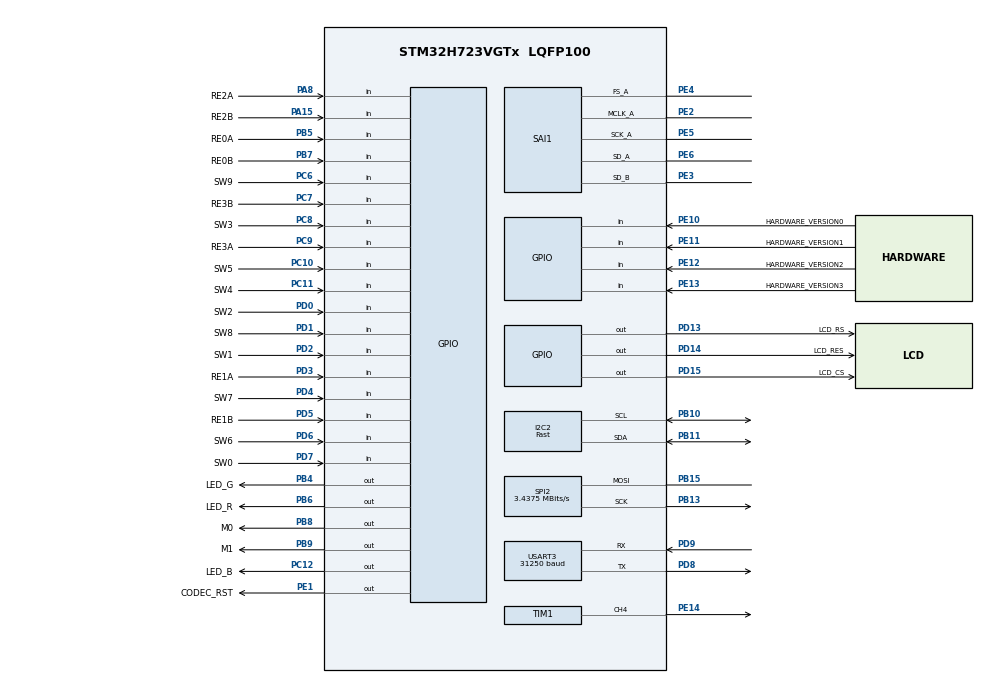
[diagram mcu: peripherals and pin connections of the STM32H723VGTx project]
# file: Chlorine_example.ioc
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CORTEX_M7.AccessPermission_Spec=MPU_REGION_FULL_ACCESS
CORTEX_M7.BaseAddress_Spec=0x30000000
CORTEX_M7.CPU_DCache=Enabled
CORTEX_M7.CPU_ICache=Enabled
CORTEX_M7.DisableExec_Spec=MPU_INSTRUCTION_ACCESS_ENABLE
CORTEX_M7.IsBufferable_Spec=MPU_ACCESS_BUFFERABLE
CORTEX_M7.Size_Spec=MPU_REGION_SIZE_512B
CORTEX_M7.SubRegionDisable_Spec=0x0
CORTEX_M7.default_mode_Activation=1
Dma.Request0=SAI1_A
Dma.Request1=SAI1_B
Dma.SAI1_A.0.Direction=DMA_PERIPH_TO_MEMORY
Dma.SAI1_A.0.EventEnable=DISABLE
Dma.SAI1_A.0.FIFOMode=DMA_FIFOMODE_DISABLE
Dma.SAI1_A.0.Instance=DMA1_Stream0
Dma.SAI1_A.0.MemDataAlignment=DMA_MDATAALIGN_WORD
Dma.SAI1_A.0.MemInc=DMA_MINC_ENABLE
Dma.SAI1_A.0.Mode=DMA_CIRCULAR
Dma.SAI1_A.0.PeriphDataAlignment=DMA_PDATAALIGN_WORD
Dma.SAI1_A.0.PeriphInc=DMA_PINC_DISABLE
Dma.SAI1_A.0.Polarity=HAL_DMAMUX_REQ_GEN_RISING
Dma.SAI1_A.0.Priority=DMA_PRIORITY_VERY_HIGH
Dma.SAI1_A.0.RequestNumber=1
Dma.SAI1_A.0.SignalID=NONE
Dma.SAI1_A.0.SyncEnable=DISABLE
Dma.SAI1_A.0.SyncPolarity=HAL_DMAMUX_SYNC_NO_EVENT
Dma.SAI1_A.0.SyncRequestNumber=1
Dma.SAI1_A.0.SyncSignalID=NONE
Dma.SAI1_B.1.Direction=DMA_MEMORY_TO_PERIPH
Dma.SAI1_B.1.EventEnable=DISABLE
Dma.SAI1_B.1.FIFOMode=DMA_FIFOMODE_DISABLE
Dma.SAI1_B.1.Instance=DMA1_Stream1
Dma.SAI1_B.1.MemDataAlignment=DMA_MDATAALIGN_WORD
Dma.SAI1_B.1.MemInc=DMA_MINC_ENABLE
Dma.SAI1_B.1.Mode=DMA_CIRCULAR
Dma.SAI1_B.1.PeriphDataAlignment=DMA_PDATAALIGN_WORD
Dma.SAI1_B.1.PeriphInc=DMA_PINC_DISABLE
Dma.SAI1_B.1.Polarity=HAL_DMAMUX_REQ_GEN_RISING
Dma.SAI1_B.1.Priority=DMA_PRIORITY_VERY_HIGH
Dma.SAI1_B.1.RequestNumber=1
Dma.SAI1_B.1.SignalID=NONE
Dma.SAI1_B.1.SyncEnable=DISABLE
Dma.SAI1_B.1.SyncPolarity=HAL_DMAMUX_SYNC_NO_EVENT
Dma.SAI1_B.1.SyncRequestNumber=1
Dma.SAI1_B.1.SyncSignalID=NONE
I2C2.I2C_Speed_Mode=I2C_Fast
I2C2.Timing=0x00D049FB
Mcu.Family=STM32H7
Mcu.Name=STM32H723VGTx
Mcu.Package=LQFP100
NVIC.DMA1_Stream0_IRQn=true\:0\:0\:false\:false\:true\:false\:true\:true
NVIC.DMA1_Stream1_IRQn=true\:0\:0\:false\:false\:true\:false\:true\:true
NVIC.PriorityGroup=NVIC_PRIORITYGROUP_4
NVIC.USART3_IRQn=true\:5\:0\:true\:false\:true\:true\:true\:true
PA13(JTMS/SWDIO).Mode=Serial_Wire
PA13(JTMS/SWDIO).Signal=DEBUG_JTMS-SWDIO
PA14(JTCK/SWCLK).Mode=Serial_Wire
PA14(JTCK/SWCLK).Signal=DEBUG_JTCK-SWCLK
PA15(JTDI).GPIO_Label=RE2B
PA15(JTDI).Signal=GPIO_Input
PA8.GPIO_Label=RE2A
PA8.Signal=GPIO_Input
PB10.Mode=I2C
PB10.Signal=I2C2_SCL
PB11.Mode=I2C
PB11.Signal=I2C2_SDA
PB13.Mode=Simplex_Bidirectional_Master
PB13.Signal=SPI2_SCK
PB15.Mode=Simplex_Bidirectional_Master
PB15.Signal=SPI2_MOSI
PB4(NJTRST).GPIO_Label=LED_G
PB4(NJTRST).Signal=GPIO_Output
PB5.GPIO_Label=RE0A
PB5.Signal=GPIO_Input
PB6.GPIO_Label=LED_R
PB6.Signal=GPIO_Output
PB7.GPIO_Label=RE0B
PB7.Signal=GPIO_Input
PB8.GPIO_Label=M0
PB8.Signal=GPIO_Output
PB9.GPIO_Label=M1
PB9.Signal=GPIO_Output
PC10.GPIO_Label=SW5
PC10.Signal=GPIO_Input
PC11.GPIO_Label=SW4
PC11.Signal=GPIO_Input
PC12.GPIO_Label=LED_B
PC12.Signal=GPIO_Output
PC6.GPIO_Label=SW9
PC6.Signal=GPIO_Input
PC7.GPIO_Label=RE3B
PC7.Signal=GPIO_Input
PC8.GPIO_Label=SW3
PC8.Signal=GPIO_Input
PC9.GPIO_Label=RE3A
PC9.Signal=GPIO_Input
PD0.GPIO_Label=SW2
PD0.Signal=GPIO_Input
PD1.GPIO_Label=SW8
PD1.Signal=GPIO_Input
PD13.GPIO_Label=LCD_RS
PD13.Signal=GPIO_Output
PD14.GPIO_Label=LCD_RES
PD14.Signal=GPIO_Output
PD15.GPIO_Label=LCD_CS
PD15.Signal=GPIO_Output
PD2.GPIO_Label=SW1
PD2.Signal=GPIO_Input
PD3.GPIO_Label=RE1A
PD3.Signal=GPIO_Input
PD4.GPIO_Label=SW7
PD4.Signal=GPIO_Input
PD5.GPIO_Label=RE1B
PD5.Signal=GPIO_Input
PD6.GPIO_Label=SW6
PD6.Signal=GPIO_Input
PD7.GPIO_Label=SW0
PD7.Signal=GPIO_Input
PD8.Mode=Asynchronous
PD8.Signal=USART3_TX
PD9.Mode=Asynchronous
PD9.Signal=USART3_RX
PE1.GPIO_Label=CODEC_RST
PE1.Signal=GPIO_Output
PE10.GPIO_Label=HARDWARE_VERSION0
PE10.Signal=GPIO_Input
PE11.GPIO_Label=HARDWARE_VERSION1
PE11.Signal=GPIO_Input
PE12.GPIO_Label=HARDWARE_VERSION2
PE12.Signal=GPIO_Input
PE13.GPIO_Label=HARDWARE_VERSION3
PE13.Signal=GPIO_Input
PE14.Signal=S_TIM1_CH4
PE2.Mode=SAI_A_MasterWithClock
PE2.Signal=SAI1_MCLK_A
PE3.Mode=SAI_B_SyncSlave
PE3.Signal=SAI1_SD_B
PE4.Mode=SAI_A_MasterWithClock
PE4.Signal=SAI1_FS_A
PE5.Mode=SAI_A_MasterWithClock
PE5.Signal=SAI1_SCK_A
PE6.Mode=SAI_A_MasterWithClock
PE6.Signal=SAI1_SD_A
PH0-OSC_IN.Mode=HSE-External-Oscillator
PH0-OSC_IN.Signal=RCC_OSC_IN
PH1-OSC_OUT.Mode=HSE-External-Oscillator
PH1-OSC_OUT.Signal=RCC_OSC_OUT
ProjectManager.HeapSize=0x200
ProjectManager.StackSize=0x400
ProjectManager.TargetToolchain=STM32CubeIDE
RCC.ADCFreq_Value=98333333.33333333
RCC.APB1Freq_Value=137500000
RCC.APB2Freq_Value=137500000
RCC.APB3Freq_Value=137500000
RCC.APB4Freq_Value=137500000
RCC.CortexFreq_Value=550000000
RCC.D1PPRE=RCC_APB3_DIV2
RCC.D2PPRE1=RCC_APB1_DIV2
RCC.D2PPRE2=RCC_APB2_DIV2
RCC.D3PPRE=RCC_APB4_DIV2
RCC.DIVM1=4
RCC.DIVM2=8
RCC.DIVM3=8
RCC.DIVN1=275
RCC.DIVN2=295
RCC.DIVN3=192
RCC.DIVP1=1
RCC.DIVP2=3
RCC.DIVP3=4
RCC.DIVQ1=5
RCC.DIVR1=5
RCC.HCLKFreq_Value=275000000
RCC.HPRE=RCC_HCLK_DIV2
RCC.HSE_VALUE=8000000
RCC.PLLSourceVirtual=RCC_PLLSOURCE_HSE
RCC.PWR_Regulator_Voltage_Scale=PWR_REGULATOR_VOLTAGE_SCALE0
RCC.SAI1CLockSelection=RCC_SAI1CLKSOURCE_PLL2
RCC.SYSCLKFreq_VALUE=550000000
RCC.SYSCLKSource=RCC_SYSCLKSOURCE_PLLCLK
RCC.USBFreq_Value=110000000
SAI1.AudioFrequency-SAI_A_MasterWithClock=SAI_AUDIO_FREQUENCY_48K
SAI1.AudioMode-SAI_A_MasterWithClock=SAI_MODEMASTER_RX
SAI1.AudioMode-SAI_B_SyncSlave=SAI_MODESLAVE_TX
SAI1.BasicDataSize-SAI_A_MasterWithClock=SAI_PROTOCOL_DATASIZE_32BIT
SAI1.BasicDataSize-SAI_B_SyncSlave=SAI_PROTOCOL_DATASIZE_32BIT
SAI1.ErrorAudioFreq-SAI_A_MasterWithClock=0.02 %
SAI1.FIFOThreshold-SAI_A_MasterWithClock=SAI_FIFOTHRESHOLD_HF
SAI1.FIFOThreshold-SAI_B_SyncSlave=SAI_FIFOTHRESHOLD_HF
SAI1.InitProtocol-SAI_A_MasterWithClock=Enable
SAI1.InitProtocol-SAI_B_SyncSlave=Enable
SAI1.Instance-SAI_A_MasterWithClock=SAI$Index_Block_A
SAI1.Instance-SAI_B_SyncSlave=SAI$Index_Block_B
SAI1.MckOutput=SAI_MCK_OUTPUT_ENABLE
SAI1.RealAudioFreq-SAI_A_MasterWithClock=48.014 KHz
SAI1.VirtualMode-SAI_A_MasterWithClock=VM_MASTER
SAI1.VirtualMode-SAI_B_SyncSlave=VM_SLAVE
SAI1.VirtualProtocol-SAI_A_BASIC=VM_BASIC_PROTOCOL
SAI1.VirtualProtocol-SAI_B_BASIC=VM_BASIC_PROTOCOL
SH.S_TIM1_CH4.0=TIM1_CH4,PWM Generation4 CH4
SPI2.BaudRatePrescaler=SPI_BAUDRATEPRESCALER_32
SPI2.CalculateBaudRate=3.4375 MBits/s
SPI2.DataSize=SPI_DATASIZE_8BIT
SPI2.Direction=SPI_DIRECTION_1LINE
SPI2.Mode=SPI_MODE_MASTER
SPI2.VirtualType=VM_MASTER
TIM1.Channel-PWM\ Generation4\ CH4=TIM_CHANNEL_4
TIM1.Period=1023
TIM1.Prescaler=0
USART3.BaudRate=31250
USART3.Mode=MODE_TX_RX
USART3.VirtualMode-Asynchronous=VM_ASYNC
VP_MEMORYMAP_VS_MEMORYMAP.Mode=CurAppReg
VP_SAI1_VP_$IpInstance_SAIA_SAI_BASIC.Mode=SAI_A_BASIC
VP_SAI1_VP_$IpInstance_SAIB_SAI_BASIC.Mode=SAI_B_BASIC
board=custom

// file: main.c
/* USER CODE BEGIN Header */
/**
  ******************************************************************************
  * @file           : main.c
  * @brief          : Main program body
  ******************************************************************************
  * @attention
  *
  * Copyright (c) 2025 STMicroelectronics.
  * All rights reserved.
  *
  * This software is licensed under terms that can be found in the LICENSE file
  * in the root directory of this software component.
  * If no LICENSE file comes with this software, it is provided AS-IS.
  *
  ******************************************************************************
  */
/* USER CODE END Header */
#include "main.h"

/* USER CODE BEGIN Includes */
#include "user_main.h"

/* USER CODE END Includes */

I2C_HandleTypeDef hi2c2;

SAI_HandleTypeDef hsai_BlockA1;
SAI_HandleTypeDef hsai_BlockB1;
DMA_HandleTypeDef hdma_sai1_a;
DMA_HandleTypeDef hdma_sai1_b;

SPI_HandleTypeDef hspi2;

TIM_HandleTypeDef htim1;

UART_HandleTypeDef huart3;

void SystemClock_Config(void);
void PeriphCommonClock_Config(void);
static void MPU_Config(void);
static void MX_GPIO_Init(void);
static void MX_DMA_Init(void);
static void MX_SPI2_Init(void);
static void MX_SAI1_Init(void);
static void MX_TIM1_Init(void);
static void MX_USART3_UART_Init(void);
static void MX_I2C2_Init(void);

int main(void)
{

  /* MPU Configuration--------------------------------------------------------*/
  MPU_Config();

  /* Enable the CPU Cache */

  /* Enable I-Cache---------------------------------------------------------*/
  SCB_EnableICache();

  /* Enable D-Cache---------------------------------------------------------*/
  SCB_EnableDCache();

  /* MCU Configuration--------------------------------------------------------*/

  /* Reset of all peripherals, Initializes the Flash interface and the Systick. */
  HAL_Init();

  /* Configure the system clock */
  SystemClock_Config();

  /* Configure the peripherals common clocks */
  PeriphCommonClock_Config();

  /* Initialize all configured peripherals */
  MX_GPIO_Init();
  MX_DMA_Init();
  MX_SPI2_Init();
  MX_SAI1_Init();
  MX_TIM1_Init();
  MX_USART3_UART_Init();
  MX_I2C2_Init();
  /* USER CODE BEGIN 2 */
  mainInit();

  /* USER CODE END 2 */

  /* Infinite loop */
  while (1)
  {

    /* USER CODE BEGIN 3 */
    mainLoop();

  }
  /* USER CODE END 3 */
}

void SystemClock_Config(void)
{
  RCC_OscInitTypeDef RCC_OscInitStruct = {0};
  RCC_ClkInitTypeDef RCC_ClkInitStruct = {0};

  /** Supply configuration update enable
  */
  HAL_PWREx_ConfigSupply(PWR_LDO_SUPPLY);

  /** Configure the main internal regulator output voltage
  */
  __HAL_PWR_VOLTAGESCALING_CONFIG(PWR_REGULATOR_VOLTAGE_SCALE0);

  while(!__HAL_PWR_GET_FLAG(PWR_FLAG_VOSRDY)) {}

  /** Initializes the RCC Oscillators according to the specified parameters
  * in the RCC_OscInitTypeDef structure.
  */
  RCC_OscInitStruct.OscillatorType = RCC_OSCILLATORTYPE_HSE;
  RCC_OscInitStruct.HSEState = RCC_HSE_ON;
  RCC_OscInitStruct.PLL.PLLState = RCC_PLL_ON;
  RCC_OscInitStruct.PLL.PLLSource = RCC_PLLSOURCE_HSE;
  RCC_OscInitStruct.PLL.PLLM = 4;
  RCC_OscInitStruct.PLL.PLLN = 275;
  RCC_OscInitStruct.PLL.PLLP = 1;
  RCC_OscInitStruct.PLL.PLLQ = 5;
  RCC_OscInitStruct.PLL.PLLR = 5;
  RCC_OscInitStruct.PLL.PLLRGE = RCC_PLL1VCIRANGE_1;
  RCC_OscInitStruct.PLL.PLLVCOSEL = RCC_PLL1VCOWIDE;
  RCC_OscInitStruct.PLL.PLLFRACN = 0;
  if (HAL_RCC_OscConfig(&RCC_OscInitStruct) != HAL_OK)
  {
    Error_Handler();
  }

  /** Initializes the CPU, AHB and APB buses clocks
  */
  RCC_ClkInitStruct.ClockType = RCC_CLOCKTYPE_HCLK|RCC_CLOCKTYPE_SYSCLK
                              |RCC_CLOCKTYPE_PCLK1|RCC_CLOCKTYPE_PCLK2
                              |RCC_CLOCKTYPE_D3PCLK1|RCC_CLOCKTYPE_D1PCLK1;
  RCC_ClkInitStruct.SYSCLKSource = RCC_SYSCLKSOURCE_PLLCLK;
  RCC_ClkInitStruct.SYSCLKDivider = RCC_SYSCLK_DIV1;
  RCC_ClkInitStruct.AHBCLKDivider = RCC_HCLK_DIV2;
  RCC_ClkInitStruct.APB3CLKDivider = RCC_APB3_DIV2;
  RCC_ClkInitStruct.APB1CLKDivider = RCC_APB1_DIV2;
  RCC_ClkInitStruct.APB2CLKDivider = RCC_APB2_DIV2;
  RCC_ClkInitStruct.APB4CLKDivider = RCC_APB4_DIV2;

  if (HAL_RCC_ClockConfig(&RCC_ClkInitStruct, FLASH_LATENCY_3) != HAL_OK)
  {
    Error_Handler();
  }
}

void PeriphCommonClock_Config(void)
{
  RCC_PeriphCLKInitTypeDef PeriphClkInitStruct = {0};

  /** Initializes the peripherals clock
  */
  PeriphClkInitStruct.PeriphClockSelection = RCC_PERIPHCLK_SAI1;
  PeriphClkInitStruct.PLL2.PLL2M = 8;
  PeriphClkInitStruct.PLL2.PLL2N = 295;
  PeriphClkInitStruct.PLL2.PLL2P = 3;
  PeriphClkInitStruct.PLL2.PLL2Q = 2;
  PeriphClkInitStruct.PLL2.PLL2R = 2;
  PeriphClkInitStruct.PLL2.PLL2RGE = RCC_PLL2VCIRANGE_0;
  PeriphClkInitStruct.PLL2.PLL2VCOSEL = RCC_PLL2VCOMEDIUM;
  PeriphClkInitStruct.PLL2.PLL2FRACN = 0;
  PeriphClkInitStruct.Sai1ClockSelection = RCC_SAI1CLKSOURCE_PLL2;
  if (HAL_RCCEx_PeriphCLKConfig(&PeriphClkInitStruct) != HAL_OK)
  {
    Error_Handler();
  }
}

static void MX_I2C2_Init(void)
{

  hi2c2.Instance = I2C2;
  hi2c2.Init.Timing = 0x00D049FB;
  hi2c2.Init.OwnAddress1 = 0;
  hi2c2.Init.AddressingMode = I2C_ADDRESSINGMODE_7BIT;
  hi2c2.Init.DualAddressMode = I2C_DUALADDRESS_DISABLE;
  hi2c2.Init.OwnAddress2 = 0;
  hi2c2.Init.OwnAddress2Masks = I2C_OA2_NOMASK;
  hi2c2.Init.GeneralCallMode = I2C_GENERALCALL_DISABLE;
  hi2c2.Init.NoStretchMode = I2C_NOSTRETCH_DISABLE;
  if (HAL_I2C_Init(&hi2c2) != HAL_OK)
  {
    Error_Handler();
  }

  /** Configure Analogue filter
  */
  if (HAL_I2CEx_ConfigAnalogFilter(&hi2c2, I2C_ANALOGFILTER_ENABLE) != HAL_OK)
  {
    Error_Handler();
  }

  /** Configure Digital filter
  */
  if (HAL_I2CEx_ConfigDigitalFilter(&hi2c2, 0) != HAL_OK)
  {
    Error_Handler();
  }

}

static void MX_SAI1_Init(void)
{

  hsai_BlockA1.Instance = SAI1_Block_A;
  hsai_BlockA1.Init.AudioMode = SAI_MODEMASTER_RX;
  hsai_BlockA1.Init.Synchro = SAI_ASYNCHRONOUS;
  hsai_BlockA1.Init.OutputDrive = SAI_OUTPUTDRIVE_DISABLE;
  hsai_BlockA1.Init.NoDivider = SAI_MASTERDIVIDER_ENABLE;
  hsai_BlockA1.Init.FIFOThreshold = SAI_FIFOTHRESHOLD_HF;
  hsai_BlockA1.Init.AudioFrequency = SAI_AUDIO_FREQUENCY_48K;
  hsai_BlockA1.Init.SynchroExt = SAI_SYNCEXT_DISABLE;
  hsai_BlockA1.Init.MonoStereoMode = SAI_STEREOMODE;
  hsai_BlockA1.Init.CompandingMode = SAI_NOCOMPANDING;
  if (HAL_SAI_InitProtocol(&hsai_BlockA1, SAI_I2S_STANDARD, SAI_PROTOCOL_DATASIZE_32BIT, 2) != HAL_OK)
  {
    Error_Handler();
  }
  hsai_BlockB1.Instance = SAI1_Block_B;
  hsai_BlockB1.Init.AudioMode = SAI_MODESLAVE_TX;
  hsai_BlockB1.Init.Synchro = SAI_SYNCHRONOUS;
  hsai_BlockB1.Init.OutputDrive = SAI_OUTPUTDRIVE_DISABLE;
  hsai_BlockB1.Init.FIFOThreshold = SAI_FIFOTHRESHOLD_HF;
  hsai_BlockB1.Init.SynchroExt = SAI_SYNCEXT_DISABLE;
  hsai_BlockB1.Init.MonoStereoMode = SAI_STEREOMODE;
  hsai_BlockB1.Init.CompandingMode = SAI_NOCOMPANDING;
  hsai_BlockB1.Init.TriState = SAI_OUTPUT_NOTRELEASED;
  if (HAL_SAI_InitProtocol(&hsai_BlockB1, SAI_I2S_STANDARD, SAI_PROTOCOL_DATASIZE_32BIT, 2) != HAL_OK)
  {
    Error_Handler();
  }

}

static void MX_SPI2_Init(void)
{

  /* SPI2 parameter configuration*/
  hspi2.Instance = SPI2;
  hspi2.Init.Mode = SPI_MODE_MASTER;
  hspi2.Init.Direction = SPI_DIRECTION_1LINE;
  hspi2.Init.DataSize = SPI_DATASIZE_8BIT;
  hspi2.Init.CLKPolarity = SPI_POLARITY_LOW;
  hspi2.Init.CLKPhase = SPI_PHASE_1EDGE;
  hspi2.Init.NSS = SPI_NSS_SOFT;
  hspi2.Init.BaudRatePrescaler = SPI_BAUDRATEPRESCALER_32;
  hspi2.Init.FirstBit = SPI_FIRSTBIT_MSB;
  hspi2.Init.TIMode = SPI_TIMODE_DISABLE;
  hspi2.Init.CRCCalculation = SPI_CRCCALCULATION_DISABLE;
  hspi2.Init.CRCPolynomial = 0x0;
  hspi2.Init.NSSPMode = SPI_NSS_PULSE_ENABLE;
  hspi2.Init.NSSPolarity = SPI_NSS_POLARITY_LOW;
  hspi2.Init.FifoThreshold = SPI_FIFO_THRESHOLD_01DATA;
  hspi2.Init.TxCRCInitializationPattern = SPI_CRC_INITIALIZATION_ALL_ZERO_PATTERN;
  hspi2.Init.RxCRCInitializationPattern = SPI_CRC_INITIALIZATION_ALL_ZERO_PATTERN;
  hspi2.Init.MasterSSIdleness = SPI_MASTER_SS_IDLENESS_00CYCLE;
  hspi2.Init.MasterInterDataIdleness = SPI_MASTER_INTERDATA_IDLENESS_00CYCLE;
  hspi2.Init.MasterReceiverAutoSusp = SPI_MASTER_RX_AUTOSUSP_DISABLE;
  hspi2.Init.MasterKeepIOState = SPI_MASTER_KEEP_IO_STATE_DISABLE;
  hspi2.Init.IOSwap = SPI_IO_SWAP_DISABLE;
  if (HAL_SPI_Init(&hspi2) != HAL_OK)
  {
    Error_Handler();
  }

}

static void MX_TIM1_Init(void)
{

  TIM_MasterConfigTypeDef sMasterConfig = {0};
  TIM_OC_InitTypeDef sConfigOC = {0};
  TIM_BreakDeadTimeConfigTypeDef sBreakDeadTimeConfig = {0};

  htim1.Instance = TIM1;
  htim1.Init.Prescaler = 0;
  htim1.Init.CounterMode = TIM_COUNTERMODE_UP;
  htim1.Init.Period = 1023;
  htim1.Init.ClockDivision = TIM_CLOCKDIVISION_DIV1;
  htim1.Init.RepetitionCounter = 0;
  htim1.Init.AutoReloadPreload = TIM_AUTORELOAD_PRELOAD_DISABLE;
  if (HAL_TIM_PWM_Init(&htim1) != HAL_OK)
  {
    Error_Handler();
  }
  sMasterConfig.MasterOutputTrigger = TIM_TRGO_RESET;
  sMasterConfig.MasterOutputTrigger2 = TIM_TRGO2_RESET;
  sMasterConfig.MasterSlaveMode = TIM_MASTERSLAVEMODE_DISABLE;
  if (HAL_TIMEx_MasterConfigSynchronization(&htim1, &sMasterConfig) != HAL_OK)
  {
    Error_Handler();
  }
  sConfigOC.OCMode = TIM_OCMODE_PWM1;
  sConfigOC.Pulse = 0;
  sConfigOC.OCPolarity = TIM_OCPOLARITY_HIGH;
  sConfigOC.OCFastMode = TIM_OCFAST_DISABLE;
  sConfigOC.OCIdleState = TIM_OCIDLESTATE_RESET;
  sConfigOC.OCNIdleState = TIM_OCNIDLESTATE_RESET;
  if (HAL_TIM_PWM_ConfigChannel(&htim1, &sConfigOC, TIM_CHANNEL_4) != HAL_OK)
  {
    Error_Handler();
  }
  sBreakDeadTimeConfig.OffStateRunMode = TIM_OSSR_DISABLE;
  sBreakDeadTimeConfig.OffStateIDLEMode = TIM_OSSI_DISABLE;
  sBreakDeadTimeConfig.LockLevel = TIM_LOCKLEVEL_OFF;
  sBreakDeadTimeConfig.DeadTime = 0;
  sBreakDeadTimeConfig.BreakState = TIM_BREAK_DISABLE;
  sBreakDeadTimeConfig.BreakPolarity = TIM_BREAKPOLARITY_HIGH;
  sBreakDeadTimeConfig.BreakFilter = 0;
  sBreakDeadTimeConfig.Break2State = TIM_BREAK2_DISABLE;
  sBreakDeadTimeConfig.Break2Polarity = TIM_BREAK2POLARITY_HIGH;
  sBreakDeadTimeConfig.Break2Filter = 0;
  sBreakDeadTimeConfig.AutomaticOutput = TIM_AUTOMATICOUTPUT_DISABLE;
  if (HAL_TIMEx_ConfigBreakDeadTime(&htim1, &sBreakDeadTimeConfig) != HAL_OK)
  {
    Error_Handler();
  }
  HAL_TIM_MspPostInit(&htim1);

}

static void MX_USART3_UART_Init(void)
{

  huart3.Instance = USART3;
  huart3.Init.BaudRate = 31250;
  huart3.Init.WordLength = UART_WORDLENGTH_8B;
  huart3.Init.StopBits = UART_STOPBITS_1;
  huart3.Init.Parity = UART_PARITY_NONE;
  huart3.Init.Mode = UART_MODE_TX_RX;
  huart3.Init.HwFlowCtl = UART_HWCONTROL_NONE;
  huart3.Init.OverSampling = UART_OVERSAMPLING_16;
  huart3.Init.OneBitSampling = UART_ONE_BIT_SAMPLE_DISABLE;
  huart3.Init.ClockPrescaler = UART_PRESCALER_DIV1;
  huart3.AdvancedInit.AdvFeatureInit = UART_ADVFEATURE_NO_INIT;
  if (HAL_UART_Init(&huart3) != HAL_OK)
  {
    Error_Handler();
  }
  if (HAL_UARTEx_SetTxFifoThreshold(&huart3, UART_TXFIFO_THRESHOLD_1_8) != HAL_OK)
  {
    Error_Handler();
  }
  if (HAL_UARTEx_SetRxFifoThreshold(&huart3, UART_RXFIFO_THRESHOLD_1_8) != HAL_OK)
  {
    Error_Handler();
  }
  if (HAL_UARTEx_DisableFifoMode(&huart3) != HAL_OK)
  {
    Error_Handler();
  }

}

static void MX_DMA_Init(void)
{

  /* DMA controller clock enable */
  __HAL_RCC_DMA1_CLK_ENABLE();

  /* DMA interrupt init */
  /* DMA1_Stream0_IRQn interrupt configuration */
  HAL_NVIC_SetPriority(DMA1_Stream0_IRQn, 0, 0);
  HAL_NVIC_EnableIRQ(DMA1_Stream0_IRQn);
  /* DMA1_Stream1_IRQn interrupt configuration */
  HAL_NVIC_SetPriority(DMA1_Stream1_IRQn, 0, 0);
  HAL_NVIC_EnableIRQ(DMA1_Stream1_IRQn);

}

static void MX_GPIO_Init(void)
{
  GPIO_InitTypeDef GPIO_InitStruct = {0};

  /* GPIO Ports Clock Enable */
  __HAL_RCC_GPIOE_CLK_ENABLE();
  __HAL_RCC_GPIOH_CLK_ENABLE();
  __HAL_RCC_GPIOB_CLK_ENABLE();
  __HAL_RCC_GPIOD_CLK_ENABLE();
  __HAL_RCC_GPIOC_CLK_ENABLE();
  __HAL_RCC_GPIOA_CLK_ENABLE();

  /*Configure GPIO pin Output Level */
  HAL_GPIO_WritePin(GPIOD, LCD_RS_Pin|LCD_RES_Pin|LCD_CS_Pin, GPIO_PIN_RESET);

  /*Configure GPIO pin Output Level */
  HAL_GPIO_WritePin(LED_B_GPIO_Port, LED_B_Pin, GPIO_PIN_RESET);

  /*Configure GPIO pin Output Level */
  HAL_GPIO_WritePin(GPIOB, LED_G_Pin|LED_R_Pin|M0_Pin|M1_Pin, GPIO_PIN_RESET);

  /*Configure GPIO pin Output Level */
  HAL_GPIO_WritePin(CODEC_RST_GPIO_Port, CODEC_RST_Pin, GPIO_PIN_RESET);

  /*Configure GPIO pins : HARDWARE_VERSION0_Pin HARDWARE_VERSION1_Pin HARDWARE_VERSION2_Pin HARDWARE_VERSION3_Pin */
  GPIO_InitStruct.Pin = HARDWARE_VERSION0_Pin|HARDWARE_VERSION1_Pin|HARDWARE_VERSION2_Pin|HARDWARE_VERSION3_Pin;
  GPIO_InitStruct.Mode = GPIO_MODE_INPUT;
  GPIO_InitStruct.Pull = GPIO_NOPULL;
  HAL_GPIO_Init(GPIOE, &GPIO_InitStruct);

  /*Configure GPIO pins : LCD_RS_Pin LCD_RES_Pin LCD_CS_Pin */
  GPIO_InitStruct.Pin = LCD_RS_Pin|LCD_RES_Pin|LCD_CS_Pin;
  GPIO_InitStruct.Mode = GPIO_MODE_OUTPUT_PP;
  GPIO_InitStruct.Pull = GPIO_NOPULL;
  GPIO_InitStruct.Speed = GPIO_SPEED_FREQ_LOW;
  HAL_GPIO_Init(GPIOD, &GPIO_InitStruct);

  /*Configure GPIO pins : SW9_Pin RE3B_Pin SW3_Pin RE3A_Pin
                           SW5_Pin SW4_Pin */
  GPIO_InitStruct.Pin = SW9_Pin|RE3B_Pin|SW3_Pin|RE3A_Pin
                          |SW5_Pin|SW4_Pin;
  GPIO_InitStruct.Mode = GPIO_MODE_INPUT;
  GPIO_InitStruct.Pull = GPIO_NOPULL;
  HAL_GPIO_Init(GPIOC, &GPIO_InitStruct);

  /*Configure GPIO pins : RE2A_Pin RE2B_Pin */
  GPIO_InitStruct.Pin = RE2A_Pin|RE2B_Pin;
  GPIO_InitStruct.Mode = GPIO_MODE_INPUT;
  GPIO_InitStruct.Pull = GPIO_NOPULL;
  HAL_GPIO_Init(GPIOA, &GPIO_InitStruct);

  /*Configure GPIO pin : LED_B_Pin */
  GPIO_InitStruct.Pin = LED_B_Pin;
  GPIO_InitStruct.Mode = GPIO_MODE_OUTPUT_PP;
  GPIO_InitStruct.Pull = GPIO_NOPULL;
  GPIO_InitStruct.Speed = GPIO_SPEED_FREQ_LOW;
  HAL_GPIO_Init(LED_B_GPIO_Port, &GPIO_InitStruct);

  /*Configure GPIO pins : SW2_Pin SW8_Pin SW1_Pin RE1A_Pin
                           SW7_Pin RE1B_Pin SW6_Pin SW0_Pin */
  GPIO_InitStruct.Pin = SW2_Pin|SW8_Pin|SW1_Pin|RE1A_Pin
                          |SW7_Pin|RE1B_Pin|SW6_Pin|SW0_Pin;
  GPIO_InitStruct.Mode = GPIO_MODE_INPUT;
  GPIO_InitStruct.Pull = GPIO_NOPULL;
  HAL_GPIO_Init(GPIOD, &GPIO_InitStruct);

  /*Configure GPIO pins : LED_G_Pin LED_R_Pin M0_Pin M1_Pin */
  GPIO_InitStruct.Pin = LED_G_Pin|LED_R_Pin|M0_Pin|M1_Pin;
  GPIO_InitStruct.Mode = GPIO_MODE_OUTPUT_PP;
  GPIO_InitStruct.Pull = GPIO_NOPULL;
  GPIO_InitStruct.Speed = GPIO_SPEED_FREQ_LOW;
  HAL_GPIO_Init(GPIOB, &GPIO_InitStruct);

  /*Configure GPIO pins : RE0A_Pin RE0B_Pin */
  GPIO_InitStruct.Pin = RE0A_Pin|RE0B_Pin;
  GPIO_InitStruct.Mode = GPIO_MODE_INPUT;
  GPIO_InitStruct.Pull = GPIO_NOPULL;
  HAL_GPIO_Init(GPIOB, &GPIO_InitStruct);

  /*Configure GPIO pin : CODEC_RST_Pin */
  GPIO_InitStruct.Pin = CODEC_RST_Pin;
  GPIO_InitStruct.Mode = GPIO_MODE_OUTPUT_PP;
  GPIO_InitStruct.Pull = GPIO_NOPULL;
  GPIO_InitStruct.Speed = GPIO_SPEED_FREQ_LOW;
  HAL_GPIO_Init(CODEC_RST_GPIO_Port, &GPIO_InitStruct);

}

 /* MPU Configuration */

void MPU_Config(void)
{
  MPU_Region_InitTypeDef MPU_InitStruct = {0};

  /* Disables the MPU */
  HAL_MPU_Disable();

  /** Initializes and configures the Region and the memory to be protected
  */
  MPU_InitStruct.Enable = MPU_REGION_ENABLE;
  MPU_InitStruct.Number = MPU_REGION_NUMBER0;
  MPU_InitStruct.BaseAddress = 0x30000000;
  MPU_InitStruct.Size = MPU_REGION_SIZE_512B;
  MPU_InitStruct.SubRegionDisable = 0x0;
  MPU_InitStruct.TypeExtField = MPU_TEX_LEVEL0;
  MPU_InitStruct.AccessPermission = MPU_REGION_FULL_ACCESS;
  MPU_InitStruct.DisableExec = MPU_INSTRUCTION_ACCESS_ENABLE;
  MPU_InitStruct.IsShareable = MPU_ACCESS_SHAREABLE;
  MPU_InitStruct.IsCacheable = MPU_ACCESS_NOT_CACHEABLE;
  MPU_InitStruct.IsBufferable = MPU_ACCESS_BUFFERABLE;

  HAL_MPU_ConfigRegion(&MPU_InitStruct);
  /* Enables the MPU */
  HAL_MPU_Enable(MPU_PRIVILEGED_DEFAULT);

}

void Error_Handler(void)
{
  __disable_irq();
  while (1)
  {
  }
}
